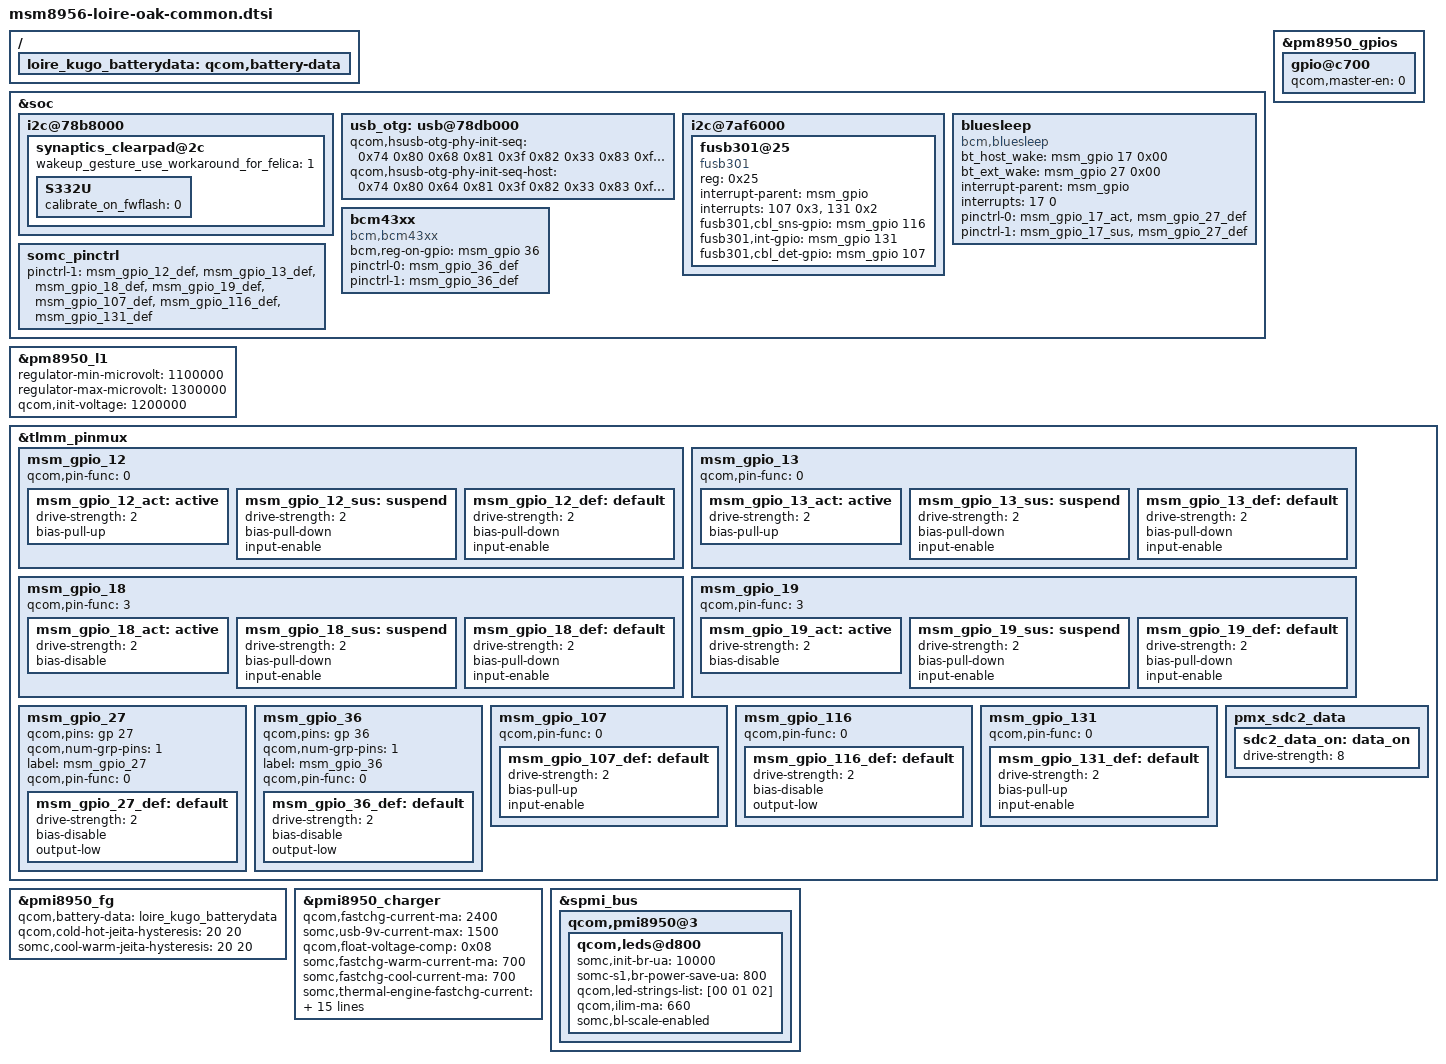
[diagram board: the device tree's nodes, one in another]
/* arch/arm/boot/dts/qcom/msm8956-loire-oak-common.dtsi
 *
 * This program is free software; you can redistribute it and/or modify
 * it under the terms of the GNU General Public License version 2 and
 * only version 2 as published by the Free Software Foundation.
 *
 * This program is distributed in the hope that it will be useful,
 * but WITHOUT ANY WARRANTY; without even the implied warranty of
 * MERCHANTABILITY or FITNESS FOR A PARTICULAR PURPOSE.  See the
 * GNU General Public License for more details.
 */

&soc {
	/* I2C : BLSP4 */
	i2c@78b8000 { /* BLSP1 QUP3 */
		synaptics_clearpad@2c {
			wakeup_gesture_use_workaround_for_felica = <1>;
			/* chip settings */
			S332U {
				calibrate_on_fwflash = <0>;
			};
		};
	};

	usb_otg: usb@78db000 {
		qcom,hsusb-otg-phy-init-seq =
			<0x74 0x80 0x68 0x81 0x3f 0x82 0x33 0x83 0xffffffff>;
		qcom,hsusb-otg-phy-init-seq-host =
			<0x74 0x80 0x64 0x81 0x3f 0x82 0x33 0x83 0xffffffff>;
	};

	i2c@7af6000 { /* BLSP2 QUP2 */
		fusb301@25 {
			status = "okay";
			compatible = "fusb301";
			reg = <0x25>;
			interrupt-parent = <&msm_gpio>;
			interrupts = <107 0x3>, <131 0x2>;
			fusb301,cbl_sns-gpio = <&msm_gpio 116 0x00>;
			fusb301,int-gpio = <&msm_gpio 131 0x00>;
			fusb301,cbl_det-gpio = <&msm_gpio 107 0x00>;
		};
	};

	bluesleep {
		compatible = "bcm,bluesleep";
		bt_host_wake = <&msm_gpio 17 0x00>; /* BT_HOST_WAKE */
		bt_ext_wake = <&msm_gpio 27 0x00>; /* BT_DEV_WAKE */
		interrupt-parent = <&msm_gpio>;
		interrupts = <17 0>;
		interrupt-names = "host_wake";
		pinctrl-names = "wake_irq_active", "wake_irq_suspend";
		pinctrl-0 = <&msm_gpio_17_act &msm_gpio_27_def>;
		pinctrl-1 = <&msm_gpio_17_sus &msm_gpio_27_def>;
	};

	bcm43xx {
		compatible = "bcm,bcm43xx";
		bcm,reg-on-gpio = <&msm_gpio 36 0x00>; /* BT_REG_ON */
		pinctrl-names = "default", "sleep";
		pinctrl-0 = <&msm_gpio_36_def>;
		pinctrl-1 = <&msm_gpio_36_def>;
	};

	somc_pinctrl: somc_pinctrl {
		/* If variant specific default setting is needed,
		   fill pinctrl-1 value in <variant>.dtsi */
		pinctrl-1 = <&msm_gpio_12_def &msm_gpio_13_def &msm_gpio_18_def
				&msm_gpio_19_def &msm_gpio_107_def &msm_gpio_116_def
				&msm_gpio_131_def>;
	};
};

/{
	loire_kugo_batterydata: qcom,battery-data {
		#include "batterydata-loire-kugo-send.dtsi"
	};
};

&pm8950_gpios {
	/* GPIO_8: NC (USB_ID_DET_N) */
	gpio@c700 {
		qcom,master-en = <0>;		/* Disable */
		status = "ok";
	};
};

/* Regulator config */
&pm8950_l1 {
	regulator-min-microvolt = <1100000>;
	regulator-max-microvolt = <1300000>;
	qcom,init-voltage = <1200000>;
	status = "okay";
};

&tlmm_pinmux {
	/* GPIO_12: TOF_INT */
	msm_gpio_12 {
		qcom,pin-func = <0>;
		msm_gpio_12_act: active {
			drive-strength = <2>;
			bias-pull-up;
		};
		msm_gpio_12_sus: suspend {
			drive-strength = <2>;
			bias-pull-down;
			input-enable;
		};
		msm_gpio_12_def: default {
			drive-strength = <2>;
			/delete-property/ bias-disable;
			/delete-property/ output-low;
			bias-pull-down;
			input-enable;
		};
	};

	/* GPIO_13: RGBC_IR_INT */
	msm_gpio_13 {
		qcom,pin-func = <0>;
		msm_gpio_13_act: active {
			drive-strength = <2>;
			bias-pull-up;
		};
		msm_gpio_13_sus: suspend {
			drive-strength = <2>;
			bias-pull-down;
			input-enable;
		};
		msm_gpio_13_def: default {
			drive-strength = <2>;
			/delete-property/ bias-disable;
			/delete-property/ output-low;
			bias-pull-down;
			input-enable;
		};
	};

	/* GPIO_18: RGBC-IR & ToF I2C SDA */
	msm_gpio_18 {
		qcom,pin-func = <3>;
		msm_gpio_18_act: active {
			drive-strength = <2>;
			bias-disable;
		};
		msm_gpio_18_sus: suspend {
			drive-strength = <2>;
			bias-pull-down;
			input-enable;
		};
		msm_gpio_18_def: default {
			drive-strength = <2>;
			/delete-property/ bias-disable;
			/delete-property/ output-low;
			bias-pull-down;
			input-enable;
		};
	};

	/* GPIO_19: CAMSENSOR_I2C_SCL */
	msm_gpio_19 {
		qcom,pin-func = <3>;
		msm_gpio_19_act: active {
			drive-strength = <2>;
			bias-disable;
		};
		msm_gpio_19_sus: suspend {
			drive-strength = <2>;
			bias-pull-down;
			input-enable;
		};
		msm_gpio_19_def: default {
			drive-strength = <2>;
			/delete-property/ bias-disable;
			/delete-property/ output-low;
			bias-pull-down;
			input-enable;
		};
	};

	/* GPIO_27: BT_DEV_WAKE */
	msm_gpio_27 {
		qcom,pins = <&gp 27>;
		qcom,num-grp-pins = <1>;
		label = "msm_gpio_27";
		qcom,pin-func = <0>;
		msm_gpio_27_def: default {
			drive-strength = <2>;
			bias-disable;
			output-low;
		};
	};

	/* GPIO_36: BT_REG_ON */
	msm_gpio_36 {
		qcom,pins = <&gp 36>;
		qcom,num-grp-pins = <1>;
		label = "msm_gpio_36";
		qcom,pin-func = <0>;
		msm_gpio_36_def: default {
			drive-strength = <2>;
			bias-disable;
			output-low;
		};
	};

	/* GPIO_107: USB_CABLE_DET_N */
	msm_gpio_107 {
		qcom,pin-func = <0>;
		msm_gpio_107_def: default {
			drive-strength = <2>;
			bias-pull-up;
			input-enable;
		};
	};

	/* GPIO_116: USB_CABLE_SENSE_EN */
	msm_gpio_116 {
		qcom,pin-func = <0>;
		msm_gpio_116_def: default {
			drive-strength = <2>;
			bias-disable;
			output-low;
		};
	};

	/* GPIO_131: USB_CC_INT */
	msm_gpio_131 {
		qcom,pin-func = <0>;
		msm_gpio_131_def: default {
			drive-strength = <2>;
			/delete-property/ bias-disable;
			/delete-property/ output-low;
			bias-pull-up;
			input-enable;
		};
	};

	pmx_sdc2_data {
		sdc2_data_on: data_on {
			drive-strength = <8>;
		};
	};
};

&pmi8950_fg {
	qcom,battery-data = <&loire_kugo_batterydata>;
	qcom,cold-hot-jeita-hysteresis = <20 20>;
	somc,cool-warm-jeita-hysteresis = <20 20>;
};

&pmi8950_charger {
	qcom,fastchg-current-ma = <2400>;
	somc,usb-9v-current-max = <1500>;
	qcom,float-voltage-comp = <0x08>;
	somc,fastchg-warm-current-ma = <700>;
	somc,fastchg-cool-current-ma = <700>;
	somc,thermal-engine-fastchg-current = <2400 2100 1880 1880 1100 700 500 300 300 300 300 300 300 0 0>;
	somc,thermal-mitigation-usb-5v = <2000 2000 2000 1500 1500 1500 1500 1500 1200 900 700 500 300 0 0>;
	somc,thermal-mitigation-usb-6v = <2000 2000 2000 1500 1500 1500 1500 1500 1200 900 700 500 300 0 0>;
	somc,thermal-mitigation-usb-7v = <2000 2000 2000 1500 1200 1200 1200 1200 1200 900 700 500 300 0 0>;
	somc,thermal-mitigation-usb-8v = <1800 1800 1800 1500 1100 1100 1100 1100 1200 900 700 500 300 0 0>;
	somc,thermal-mitigation-usb-9v = <1600 1600 1600 1500 1000 1000 1000 1000 1200 900 700 500 300 0 0>;
	somc,limit-usb-5v-level = <8>;
	/delete-property/ id_poll_enable;
	/delete-property/ id_poll_up_interval;
	/delete-property/ id_poll_up_period;
	/delete-property/ id_poll_pd_gpio;
	/delete-property/ id_poll_pd_invert;
	qcom,external-typec;
	qcom,typec-psy-name = "typec";
	somc,typec-current-max = <2000>;
};

&spmi_bus {
	qcom,pmi8950@3 {
		qcom,leds@d800 {
			somc,init-br-ua = <10000>;
			somc-s1,br-power-save-ua = <800>;
			qcom,led-strings-list = [00 01 02];
			qcom,ilim-ma = <660>;
			somc,bl-scale-enabled;
		};
	};
};
